# 3065ARPIRZ register map
File version: 1.0
Registers are 32-bit, access per field, reset 0x0 unless marked. A register's access mark holds for its fields unless they carry their own. Offsets are from the block's base; [hi:lo] are bit positions.

## FLASH — HIEFC_COMMON_REGS peripheral interface
Base 0x14710000
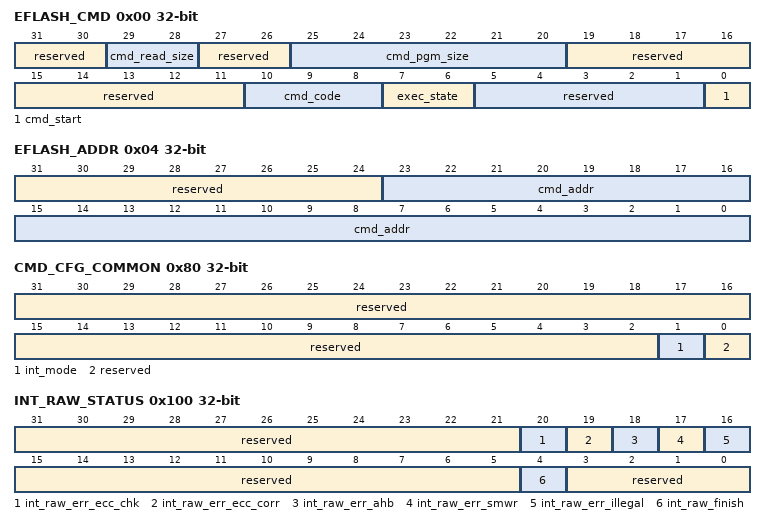
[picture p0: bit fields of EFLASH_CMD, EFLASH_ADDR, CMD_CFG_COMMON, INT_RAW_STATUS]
0x00 EFLASH_CMD — 命令寄存器。
  [31:30] reserved ro — 保留。
  [29:28] cmd_read_size rw — Read Size 寄存器 Unit:Word（32bit） 。 00： 1（cmd_addr 需要按 32bit 对齐） ； 01： 4（cmd_addr 需要按 128bit 对 齐） ； 10： 8（cmd_addr 需要按 128bit 对 齐） ； 11： 12（cmd_addr 需要按 128bit 对 齐） 。
  [27:26] reserved ro — 保留。
  [25:20] cmd_pgm_size rw — Program Size寄存器,Unit:Word（32bit）。 0x1: 4 ； 0x2: 8 ； … 0x1F:124； 0x20:128； others:非法值。 cmd_addr+cmd_pgm_size寻址范围不能跨越row（128Word）。
  [19:11] reserved ro — 保留。
  [10:8] cmd_code rw — 操作字寄存器。 001： READ； 010： main_rgn0/main_rgn1 Program； 011： info_rgn0/info_rgn1 Program； 100： main_rgn0/main_rgn1 Erase； 101： info_rgn0/info_rgn1 Erase； 110： Mass Erase（包含 main_rgn0/main_rgn1，不包含 info_rgn0/info_rgn1） ； 其他： 无操作。
  [7:6] exec_state ro — Flash CMD 执行状态 debug 寄存器。 00（IDLE） ： 无操作或操作已完成； 01（RUNNING） ： 有操作在执行； 10（FINISH） ： 操作完成，但完成标示未 清除（中断模式才生效） 。 其他： 保留。
  [5:1] reserved ro — 保留。
  [0] cmd_start rw — Flash CMD 操作启动寄存器。 写 1 启动 Flash CMD 操作； 写 0 无影响； 读 1 Flash CMD 操作未完成； 读 0 Flash CMD 操作完成或无操作。
0x04 EFLASH_ADDR — 地址寄存器。
  [31:24] reserved ro — 保留。
  [23:0] cmd_addr rw — Program、 Erase 或者 Read 的起始地址寄 存器， Unit:Byte（8bit） 。 Main_rgn0/main_rgn1 起始地 址:0x00_0000（Unit:Byte） ； Info_rgn0/info_rgn1 起始地址:0x80_0000（Unit:Byte）。 注意：低 2bit 无法写入。
0x80 CMD_CFG_COMMON — CMD配置寄存器。
  [31:2] reserved ro — 保留。
  [1] int_mode rw — CMD 操作方式控制寄存器。 0： 轮询方式； 1： 中断方式，此方式 Flash CMD 操作完成后需要配置int_clr_finish 清除完成标识，方可进行下一次操作。
  [0] reserved ro — 保留。
0x100 INT_RAW_STATUS ro — 中断原始状态寄存器。
  [31:21] reserved — 保留。
  [20] int_raw_err_ecc_chk — Main_rgn0/main_rgn1读数据ecc检验错误原始中断寄存器。 0:无错误，或者读数据ecc检错功能未使能； 1:发生ecc检查错误。
  [19] int_raw_err_ecc_corr — Main_rgn0/main_rgn1 读数据 ECC 纠正错误原始中断寄存器。 0： 无错误，或者读数据 ECC 纠错功能未使能； 1： 发生无法纠正的 ECC 错误。
  [18] int_raw_err_ahb — ahb请求错误原始中断寄存器。 0:无错误； 1： ahb 读请求地址超过Main_rgn0/main_rgn1 范围或发生了 AHB 写请求。
  [17] int_raw_err_smwr — Pgm/erase 错误原始中断状态寄存器。 0： pass； 1： failure。
  [16] int_raw_err_illegal — 非法 Flash CMD 操作错误原始中断寄存器。 0： 无错误； 1： 存在 Flash CMD 操作错误，具体错误，需要查询 FLASH_STATUS 寄存器。
  [15:5] reserved — 保留。
  [4] int_raw_finish — Flash CMD操作完成原始中断寄存器。 0:无操作或者操作未完成； 1:操作已完成。
  [3:0] reserved — 保留。
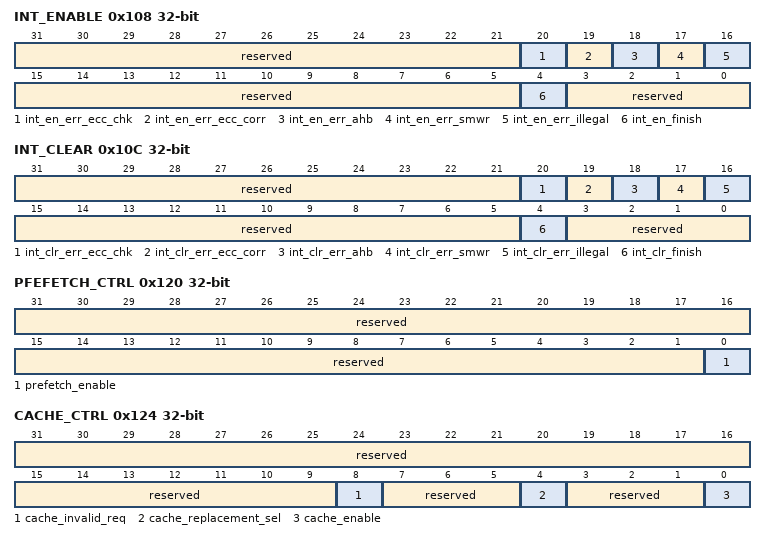
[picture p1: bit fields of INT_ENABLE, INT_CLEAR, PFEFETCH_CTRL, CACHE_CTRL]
0x108 INT_ENABLE — 中断使能配置寄存器。
  [31:21] reserved ro — 保留。
  [20] int_en_err_ecc_chk rw — Main_rgn0/main_rgn1 读数据ecc检验错误中断使能寄存器。 0:不使能，上报原始中断，不上报中断状态，不上报CPU中断； 1:使能，上报原始中断，上报中断状态，上报CPU中断。
  [19] int_en_err_ecc_corr rw — Main_rgn0/main_rgn1读数据ecc纠正错误中断使能寄存器。 0:不使能，上报原始中断，不上报中断状态，不上报CPU中断； 1:使能，上报原始中断，上报中断状态，上报CPU中断。
  [18] int_en_err_ahb rw — ahb请求错误中断使能寄存器。 0:不使能，上报原始中断，不上报中断状态，不上报CPU中断； 1:使能，上报原始中断，上报中断状态，上报CPU中断。
  [17] int_en_err_smwr rw — Pgm/erase错误中断使能寄存器。 0:不使能，上报原始中断，不上报中断状态，不上报CPU中断； 1:使能，上报原始中断，上报中断状态，上报CPU中断。
  [16] int_en_err_illegal rw — 非法Flash CMD操作错误中断使能寄存器。 0:不使能，上报原始中断，不上报中断状态，不上报CPU中断； 1:使能，上报原始中断，上报中断状态，上报CPU中断。
  [15:5] reserved ro — 保留。
  [4] int_en_finish rw — Flash CMD操作完成中断使能寄存器。 0:不使能，上报原始中断，不上报中断状态，不上报CPU中断； 1:使能，上报原始中断，上报中断状态，上报CPU中断。
  [3:0] reserved ro — 保留。
0x10C INT_CLEAR — 中断清除寄存器。
  [31:21] reserved ro — 保留。
  [20] int_clr_err_ecc_chk rw write-1-clears — Main_rgn0/main_rgn1读数据ecc检验错误中断清除寄存器。 0:不清除； 1:清除原始中断与中断状态。
  [19] int_clr_err_ecc_corr rw write-1-clears — Main_rgn0/main_rgn1 读数据ecc纠正错误中断清除寄存器。 0:不清除； 1:清除原始中断与中断状态。
  [18] int_clr_err_ahb rw write-1-clears — ahb请求错误中断清除寄存器。 0:不清除； 1:清除原始中断与中断状态。
  [17] int_clr_err_smwr rw write-1-clears — Pgm/erase错误中断清除寄存器。 0:不清除； 1:清除原始中断与中断状态。
  [16] int_clr_err_illegal rw write-1-clears — 非法Flash CMD操作错误中断清除寄存器。 0:不清除； 1:清除原始中断与中断状态。
  [15:5] reserved ro — 保留。
  [4] int_clr_finish rw write-1-clears — Flash CMD操作完成中断清除寄存器。 0:不清除； 1:清除原始中断与中断状态。
  [3:0] reserved ro — 保留。
0x120 PFEFETCH_CTRL — 预取控制寄存器。
  [31:1] reserved ro — 保留。
  [0] prefetch_enable rw — 预取使能控制寄存器。 0:预取使能关闭； 1:每次AHB传输完成尾地址向前预取32byte数据（以16byte对齐）。
0x124 CACHE_CTRL — Cache控制寄存器。
  [31:9] reserved ro — 保留。
  [8] cache_invalid_req rw — Cache数据无效请求控制寄存器 。 写1:请求Cache invalid，逻辑完成invalid后自动清除该bit； 写0无效； 读0:最近一次invalid请求已完成； 读1:最近一次invalid请求未完成。
  [7:5] reserved ro — 保留。
  [4] cache_replacement_sel rw — Cache替换策略选择控制寄存器。 0:PLRU策略； 1:Round Robin策略。
  [3:1] reserved ro — 保留。
  [0] cache_enable rw — Cache使能控制寄存器。 0:Cache使能关闭； 1:Cache使能打开，AHB传输数据将会查询Cache，Cache Hit则数据从Cache获取，Cache miss则数据从eFlash获取，并将此地址数据缓存进入Cache。
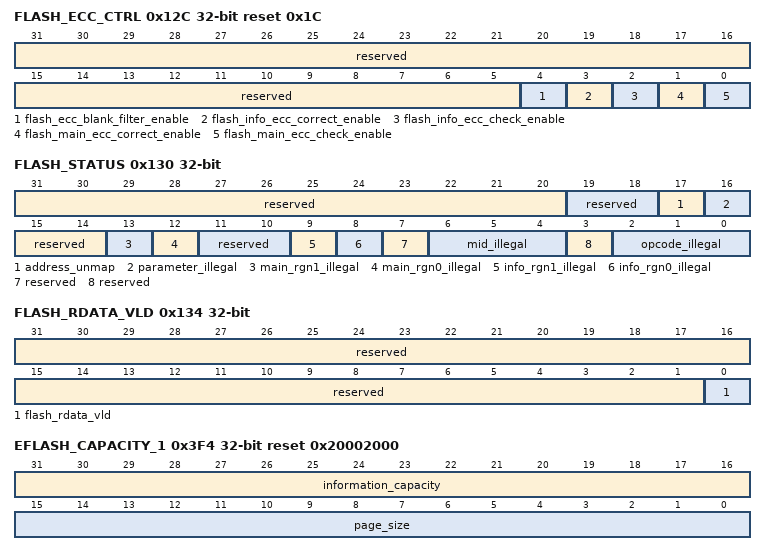
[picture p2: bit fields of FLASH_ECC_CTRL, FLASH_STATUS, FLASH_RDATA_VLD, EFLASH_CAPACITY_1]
0x12C FLASH_ECC_CTRL reset 0x1C — Flash ECC检错纠错使能控制寄存器。
  [31:5] reserved ro — 保留。
  [4] flash_ecc_blank_filter_enable rw — Flash 未编程区域 ECC 屏蔽过滤使能控制（全1判断为未编程区域）。 0:不使能此功能，所有read访问数据都根据flash_ecc_correct_enable、flash_ecc_check_enable配置进行相应的ECC检查或者纠正； 1:使能此功能，检查read访问数据内容，只有非全1数据根据flash_ecc_correct_enable、flash_ecc_check_enable配置进行相应的ECC检查或者纠正。
  [3] flash_info_ecc_correct_enable rw — Flash Information region ECC纠错功能控制。 0:回读数据发生错误时，不进行ECC纠错； 1:回读数据发生1bit错误时，进行ECC纠错。
  [2] flash_info_ecc_check_enable rw — Flash Information region 检错使能控制（Program 强制ECC打开）。 0:回读数据不进行ECC检查； 1:回读数据进行ECC检查。
  [1] flash_main_ecc_correct_enable rw — Flash Main_rgn0/main_rgn1 ECC纠错功能控制。 0： 回读数据发生错误时，不进行ECC 纠错； 1： 回读数据发生 1bit 错误时，进行ECC 纠错。
  [0] flash_main_ecc_check_enable rw — Flash Main_rgn0/main_rgn1 检错使能控制（Program 强制 ECC 打开） 。 0： 回读数据不进行 ECC 检查； 1： 回读数据进行 ECC 检查。
0x130 FLASH_STATUS ro — CMD操作FLASH状态寄存器。
  [31:20] reserved — 保留。
  [19:18] reserved — 保留。
  [17] address_unmap — Flash CMD 操作地址是否越界指示寄存器。 0： 无错误； 1： 地址越界错误。
  [16] parameter_illegal — Flash CMD 操作参数是否有效指示寄存器。 0： 无错误； 1： 操作参数错误。
  [15:14] reserved — 保留。
  [13] main_rgn1_illegal — Flash CMD 操作 main_rgn1 是否发生非法访问指示寄存器。 0： 无错误； 1： main_rgn1 发生非法访问。
  [12] main_rgn0_illegal — Flash CMD 操作 main_rgn0 是否发生非法访问指示寄存器。 0： 无错误； 1： main_rgn0 发送非法访问。
  [11:10] reserved — 保留。
  [9] info_rgn1_illegal — Flash CMD 操作 info_rgn1 是否发生非法访问指示寄存器。 0： 无错误； 1： info_rgn1 区发生非法访问。
  [8] info_rgn0_illegal — Flash CMD 操作 info_rgn0 是否发生非法访问指示寄存器。 0： 无错误； 1： info_rgn0 区发生非法访问。
  [7] reserved — 保留。
  [6:4] mid_illegal — 发生非法访问时， Flash CMD 寄存器非法mid value。
  [3] reserved — 保留。
  [2:0] opcode_illegal — 发生非法访问时， Flash CMD 寄存器非法opcode value。
0x134 FLASH_RDATA_VLD ro — FLASH读数据有效指示寄存器。
  [31:1] reserved — 保留。
  [0] flash_rdata_vld — 读数据FIFO数据有效指示寄存器。 0:读数据fifo数据有效； 1:读数据fifo数据无效。
0x138 AHB_ERR_ADDR ro — AHB错误请求地址记录寄存器。
  [31:0] ahb_err_address — int_raw_err_ahb发生时，记录第一次发生ahb错误访问的地址信息，包括越界与ahb 写操作。 配置中断清除寄存器int_clr_err_ahb时，该寄存器清0，并开始记录下一次错误请求地址信息。
0x200 MAGIC_LOCK rw — CMD操作魔术字保护寄存器。
  [31:0] magic_lock — 写入0xFEDC_BA98，魔术字解锁，CMD相关操作寄存器写入权限打开， 写入其他数值，魔术字锁定，CMD相关操作寄存器写入权限关闭。 读出0xFEDC_BA98表示解锁，读出0表示锁定。 默认为解锁状态。 CMD 相关操作寄存器包括： EFLASH_CMD、 EFLASH_ADDR、FLASH_RDATA_VLD、FLASH_RDATA。
0x3F0 EFLASH_CAPACITY_0 ro reset 0x28000 — 模块信息寄存器0。
  [31:0] main_capacity — Main_rgn0 与 main_rgn1 容量指示寄存器 unit:byte 。
0x3F4 EFLASH_CAPACITY_1 ro reset 0x20002000 — 模块信息寄存器1。
  [31:16] information_capacity — info_rgn0/info_rgn1容量指示寄存器 unit:byte。 8KB 。
  [15:0] page_size — eFlash page容量指示寄存器 unit:byte。 8KB 。
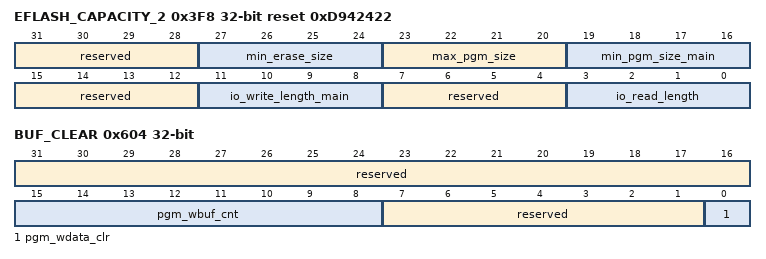
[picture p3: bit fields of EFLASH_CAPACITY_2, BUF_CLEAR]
0x3F8 EFLASH_CAPACITY_2 ro reset 0xD942422 — 模块信息寄存器2。
  [31:28] reserved — 保留。
  [27:24] min_erase_size — 最小擦除size（2**n）unit:Byte。 8KB。
  [23:20] max_pgm_size — 连续编程最大size（2**n） Byte。 512Bytes。
  [19:16] min_pgm_size_main — main_rgn0/main_rgn1 最小编程size(2**n) Byte。 16Byte。
  [15:12] reserved
  [11:8] io_write_length_main — 写 main_rgn0/main_rgn1 IO size (2**n) Byte（不算 ECC bit） 。 16Byte。
  [7:4] reserved
  [3:0] io_read_length — 读IO size （2**n） Byte。 4byte。
0x400 PGM_WDATA wo — 编程数据寄存器。
  [31:0] pgm_wdata — 编程数据Buffer寄存器。 0x400-0x5FC，都映射到同一写数据寄存器； 写0x400-0x5FC任意一个寄存器一次，写数据buffer数据增加一个Word（32bits），此buffer数据先进先出。
0x600 FLASH_RDATA ro — 读数据寄存器。
  [31:0] flash_rdata — 读数据FIFO寄存器。 cmd操作apb read时，读一次该寄存器，读取一个Word（32bits）数据。
0x604 BUF_CLEAR — 编程数据Buffer清理寄存器。
  [31:16] reserved ro — 保留。
  [15:8] pgm_wbuf_cnt ro — 编程数据buffer当前存量数据size指示寄存器 unit:Word(32bit)。
  [7:1] reserved ro — 保留。
  [0] pgm_wdata_clr rw write-1-clears — 编程数据Buffer数据清除控制寄存器。 写1:清除当前Buffer中残留数据； 写0:无效果。
